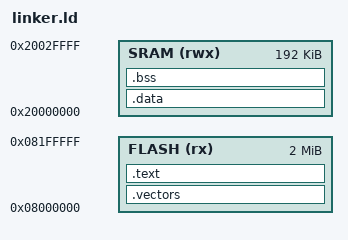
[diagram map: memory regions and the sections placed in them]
/*
 * STM32F439 Linker Script
 *
 * Memory Map:
 *   Flash: 0x08000000 - 2MB
 *   SRAM1: 0x20000000 - 112KB
 *   SRAM2: 0x2001C000 - 16KB
 *   SRAM3: 0x20020000 - 64KB
 */

MEMORY
{
    FLASH (rx)  : ORIGIN = 0x08000000, LENGTH = 2M
    SRAM (rwx)  : ORIGIN = 0x20000000, LENGTH = 192K
}

ENTRY(Reset_Handler)

SECTIONS
{
    .vectors :
    {
        . = ALIGN(4);
        KEEP(*(.vectors))
        . = ALIGN(4);
    } > FLASH

    .text :
    {
        . = ALIGN(4);
        *(.text)
        *(.text*)
        *(.rodata)
        *(.rodata*)
        . = ALIGN(4);
        _etext = .;
    } > FLASH

    .data : AT(_etext)
    {
        . = ALIGN(4);
        _sdata = .;
        *(.data)
        *(.data*)
        . = ALIGN(4);
        _edata = .;
    } > SRAM

    .bss :
    {
        . = ALIGN(4);
        _sbss = .;
        *(.bss)
        *(.bss*)
        *(COMMON)
        . = ALIGN(4);
        _ebss = .;
    } > SRAM

    _estack = ORIGIN(SRAM) + LENGTH(SRAM);
}
